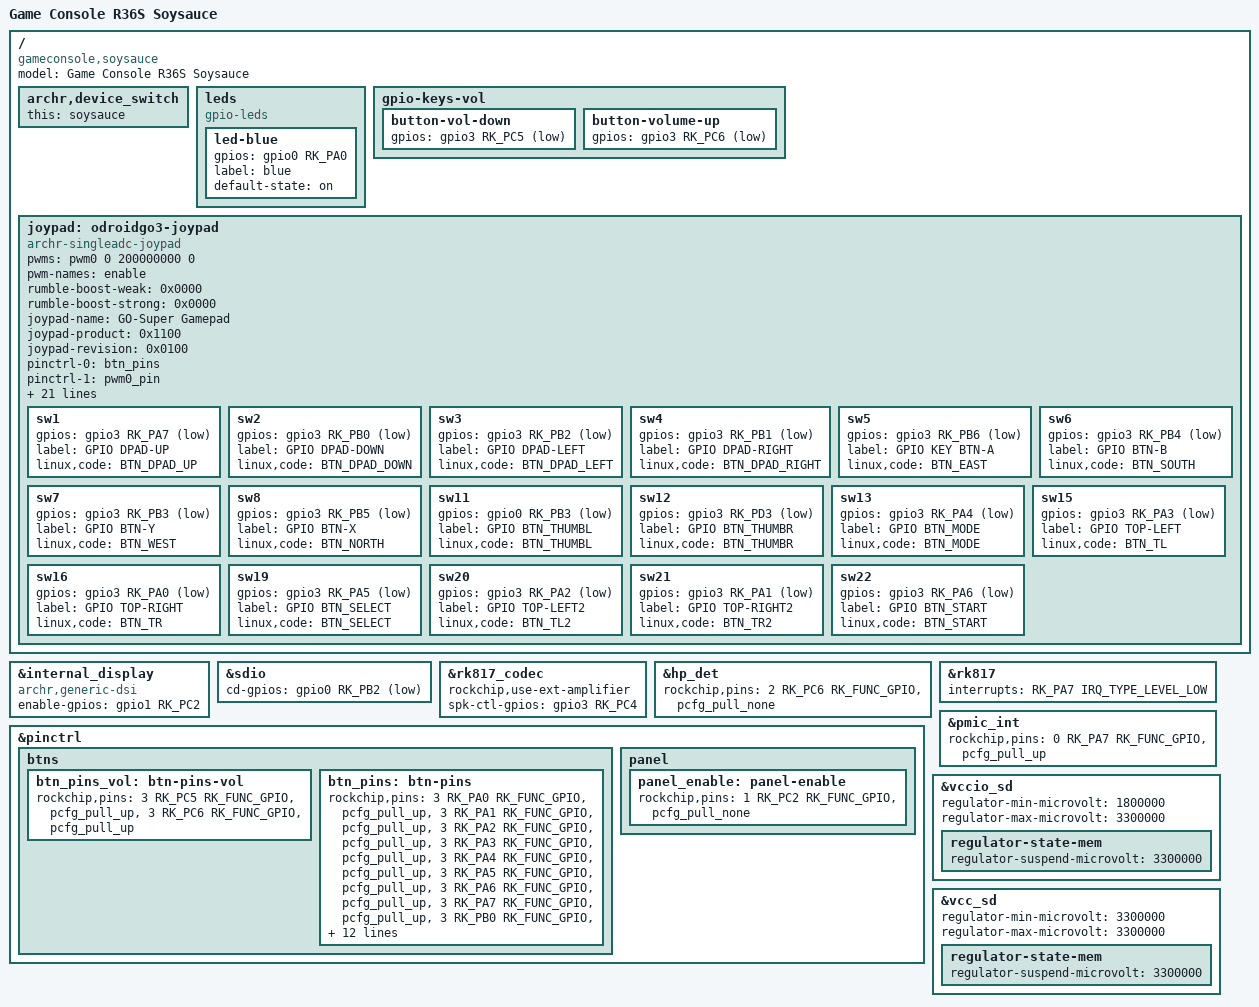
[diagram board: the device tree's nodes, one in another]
// SPDX-License-Identifier: (GPL-2.0+ OR MIT)
/*
 * Copyright (C) 2026 ArchR (https://github.com/archr-linux/Arch-R)
 *
 * Device tree for R36S "soysauce" variant (Y3506 boards).
 * Hardware differences from standard R36S:
 *   - All buttons on GPIO3 (standard uses GPIO1/GPIO2)
 *   - Analog mux on GPIO0 (standard uses GPIO3)
 *   - Panel reset GPIO: GPIO3_PB0
 *   - Panel enable GPIO: GPIO1_PC2
 *   - amux-channel-mapping reordered
 *   - Different joypad product ID (0x1100 "GO-Super Gamepad")
 */

/dts-v1/;
#include "rk3326-gameconsole-r3xs.dtsi"
#include "rk3326-device-group-r36.dtsi"

/ {
	model = "Game Console R36S Soysauce";
	compatible = "gameconsole,soysauce", "gameconsole,r36s", "rockchip,rk3326";

	archr,device_switch {
		this = "soysauce";
	};

	/* LED indicators (soysauce-specific). Only the blue power LED is
	 * GPIO-driven; the red one is hardwired to the charger IC (toggling
	 * the old led-red node on GPIO0_A5 did nothing on hardware, so the
	 * node was a phantom and got dropped). The line is active HIGH:
	 * declaring it active low inverted the whole ES power LED menu
	 * (off lit the LED, on darkened it, heartbeat looked normal). */
	leds {
		compatible = "gpio-leds";

		led-blue {
			gpios = <&gpio0 RK_PA0 GPIO_ACTIVE_HIGH>;
			label = "blue";
			default-state = "on";
		};
	};

	/* Volume buttons: GPIO3_PC6/PC5 on soysauce (base has GPIO2_PA0/PA1) */
	gpio-keys-vol {
		button-vol-down {
			gpios = <&gpio3 RK_PC5 GPIO_ACTIVE_LOW>;
		};

		button-volume-up {
			gpios = <&gpio3 RK_PC6 GPIO_ACTIVE_LOW>;
		};
	};

	joypad: odroidgo3-joypad {
		/* All Y3506 (soysauce) boards we've seen use single-ADC + amux
		 * (amux-count=4, amux-channel-mapping=<3 2 0 1>), which is the
		 * archr-singleadc-joypad driver's wire protocol. The previous
		 * "archr-joypad" / "odroidgo3-joypad" compat strings bind to
		 * the multi-ADC driver, which ignores the amux-* props and
		 * leaves the analog sticks dead (see archr-linux/Arch-R#27).
		 */
		compatible = "archr-singleadc-joypad";
		pwms = <&pwm0 0 200000000 0>;
		pwm-names = "enable";
		rumble-boost-weak = <0x0000>;
		rumble-boost-strong = <0x0000>;

		joypad-name = "GO-Super Gamepad";
		joypad-product = <0x1100>;
		joypad-revision = <0x0100>;

		status = "okay";

		pinctrl-names = "default";
		pinctrl-0 = <&btn_pins>;
		pinctrl-1 = <&pwm0_pin>;

		/* Analog mux on GPIO0 (different from standard R36S) */
		io-channel-names = "amux_adc";
		io-channels = <&saradc 1>;

		amux-count = <4>;
		amux-channel-mapping = <3 2 0 1>;
		amux-a-gpios = <&gpio0 RK_PB5 GPIO_ACTIVE_LOW>;
		amux-b-gpios = <&gpio0 RK_PB4 GPIO_ACTIVE_LOW>;
		amux-en-gpios = <&gpio0 RK_PC1 GPIO_ACTIVE_LOW>;

		button-adc-scale = <2>;
		button-adc-deadzone = <64>;
		button-adc-fuzz = <32>;
		button-adc-flat = <32>;

		/*
		 * The Y3506 analog sticks only swing to ~76% of the declared
		 * range at full deflection with the default 200 gain (measured
		 * ~1365 of 1800 via evtest), so partial pushes never cross the
		 * EmulationStation navigation threshold and menu scrolling needs
		 * several flicks per item. Bump the gain so full deflection
		 * saturates the axis; games keep all but the top few percent of
		 * travel. The R36S/eeclone pots reach full range at 200, this is
		 * a Y3506-specific calibration.
		 */
		abs_x-p-tuning = <280>;
		abs_x-n-tuning = <280>;
		abs_y-p-tuning = <280>;
		abs_y-n-tuning = <280>;
		abs_rx-p-tuning = <280>;
		abs_rx-n-tuning = <280>;
		abs_ry-p-tuning = <280>;
		abs_ry-n-tuning = <280>;

		poll-interval = <10>;

		invert-absx;
		invert-absy;

		/* All buttons on GPIO3 (soysauce layout) */
		sw1 {
			gpios = <&gpio3 RK_PA7 GPIO_ACTIVE_LOW>;
			label = "GPIO DPAD-UP";
			linux,code = <BTN_DPAD_UP>;
		};
		sw2 {
			gpios = <&gpio3 RK_PB0 GPIO_ACTIVE_LOW>;
			label = "GPIO DPAD-DOWN";
			linux,code = <BTN_DPAD_DOWN>;
		};
		sw3 {
			gpios = <&gpio3 RK_PB2 GPIO_ACTIVE_LOW>;
			label = "GPIO DPAD-LEFT";
			linux,code = <BTN_DPAD_LEFT>;
		};
		sw4 {
			gpios = <&gpio3 RK_PB1 GPIO_ACTIVE_LOW>;
			label = "GPIO DPAD-RIGHT";
			linux,code = <BTN_DPAD_RIGHT>;
		};
		sw5 {
			gpios = <&gpio3 RK_PB6 GPIO_ACTIVE_LOW>;
			label = "GPIO KEY BTN-A";
			linux,code = <BTN_EAST>;
		};
		sw6 {
			gpios = <&gpio3 RK_PB4 GPIO_ACTIVE_LOW>;
			label = "GPIO BTN-B";
			linux,code = <BTN_SOUTH>;
		};
		sw7 {
			gpios = <&gpio3 RK_PB3 GPIO_ACTIVE_LOW>;
			label = "GPIO BTN-Y";
			linux,code = <BTN_WEST>;
		};
		sw8 {
			gpios = <&gpio3 RK_PB5 GPIO_ACTIVE_LOW>;
			label = "GPIO BTN-X";
			linux,code = <BTN_NORTH>;
		};
		sw11 {
			gpios = <&gpio0 RK_PB3 GPIO_ACTIVE_LOW>;
			label = "GPIO BTN_THUMBL";
			linux,code = <BTN_THUMBL>;
		};
		sw12 {
			gpios = <&gpio3 RK_PD3 GPIO_ACTIVE_LOW>;
			label = "GPIO BTN_THUMBR";
			linux,code = <BTN_THUMBR>;
		};
		sw13 {
			gpios = <&gpio3 RK_PA4 GPIO_ACTIVE_LOW>;
			label = "GPIO BTN_MODE";
			linux,code = <BTN_MODE>;
		};
		sw15 {
			gpios = <&gpio3 RK_PA3 GPIO_ACTIVE_LOW>;
			label = "GPIO TOP-LEFT";
			linux,code = <BTN_TL>;
		};
		sw16 {
			gpios = <&gpio3 RK_PA0 GPIO_ACTIVE_LOW>;
			label = "GPIO TOP-RIGHT";
			linux,code = <BTN_TR>;
		};
		sw19 {
			gpios = <&gpio3 RK_PA5 GPIO_ACTIVE_LOW>;
			label = "GPIO BTN_SELECT";
			linux,code = <BTN_SELECT>;
		};
		sw20 {
			gpios = <&gpio3 RK_PA2 GPIO_ACTIVE_LOW>;
			label = "GPIO TOP-LEFT2";
			linux,code = <BTN_TL2>;
		};
		sw21 {
			gpios = <&gpio3 RK_PA1 GPIO_ACTIVE_LOW>;
			label = "GPIO TOP-RIGHT2";
			linux,code = <BTN_TR2>;
		};
		sw22 {
			gpios = <&gpio3 RK_PA6 GPIO_ACTIVE_LOW>;
			label = "GPIO BTN_START";
			linux,code = <BTN_START>;
		};
	};
};

/* Soysauce panel: same reset GPIO as base (GPIO3_PC0), add enable GPIO */
&internal_display {
	compatible = "archr,generic-dsi", "rocknix,generic-dsi";
	enable-gpios = <&gpio1 RK_PC2 GPIO_ACTIVE_HIGH>;
};

/*
 * Slot 2 (TF2) card detect. The base puts it on GPIO3_PB6, which is BTN-A
 * here; every Y3506 vendor DTB (V03 to V05) wires it to GPIO0_PB2, free on
 * this board since the PMIC interrupt moved to GPIO0_PA7 (see &rk817). With
 * the real line the slot is hot-pluggable and a card that fails its first
 * init gets probed again on reinsertion, instead of the one boot-time try a
 * non-removable slot gets. The RK915 wifi overlay sets non-removable on
 * &sdio itself, which leaves this line inert on those boards.
 */
&sdio {
	cd-gpios = <&gpio0 RK_PB2 GPIO_ACTIVE_LOW>;
};

&rk817_codec {
	/*
	 * The loudspeaker is not on the rk817 class-D SPKO output; it hangs off
	 * the analog headphone output through an external amp enabled by
	 * spk-ctl-gpios. Tell the codec driver to route the speaker path through
	 * the headphone DACs and toggle that GPIO (see the rk817 ext-amplifier
	 * patch) instead of driving the unused class-D.
	 */
	rockchip,use-ext-amplifier;
	spk-ctl-gpios = <&gpio3 RK_PC4 GPIO_ACTIVE_HIGH>;
};

/*
 * The shared r3xs hp-det pin uses pcfg_pull_down, which on this board pins the
 * headphone-detect line low forever (insertion is never seen). The stock R35S
 * DTB leaves it at pcfg_pull_none and lets the jack circuit drive the level, so
 * override the pull here for the Soysauce only.
 */
&hp_det {
	rockchip,pins = <2 RK_PC6 RK_FUNC_GPIO &pcfg_pull_none>;
};

&pinctrl {
	btns {
		btn_pins_vol: btn-pins-vol {
			rockchip,pins = <3 RK_PC5 RK_FUNC_GPIO &pcfg_pull_up>,
					<3 RK_PC6 RK_FUNC_GPIO &pcfg_pull_up>;
		};

		btn_pins: btn-pins {
			rockchip,pins =
				<3 RK_PA0 RK_FUNC_GPIO &pcfg_pull_up>,
				<3 RK_PA1 RK_FUNC_GPIO &pcfg_pull_up>,
				<3 RK_PA2 RK_FUNC_GPIO &pcfg_pull_up>,
				<3 RK_PA3 RK_FUNC_GPIO &pcfg_pull_up>,
				<3 RK_PA4 RK_FUNC_GPIO &pcfg_pull_up>,
				<3 RK_PA5 RK_FUNC_GPIO &pcfg_pull_up>,
				<3 RK_PA6 RK_FUNC_GPIO &pcfg_pull_up>,
				<3 RK_PA7 RK_FUNC_GPIO &pcfg_pull_up>,
				<3 RK_PB0 RK_FUNC_GPIO &pcfg_pull_up>,
				<3 RK_PB1 RK_FUNC_GPIO &pcfg_pull_up>,
				<3 RK_PB2 RK_FUNC_GPIO &pcfg_pull_up>,
				<3 RK_PB3 RK_FUNC_GPIO &pcfg_pull_up>,
				<3 RK_PB4 RK_FUNC_GPIO &pcfg_pull_up>,
				<3 RK_PB5 RK_FUNC_GPIO &pcfg_pull_up>,
				<3 RK_PB6 RK_FUNC_GPIO &pcfg_pull_up>,
				<3 RK_PD3 RK_FUNC_GPIO &pcfg_pull_up>,
				<0 RK_PB3 RK_FUNC_GPIO &pcfg_pull_up>,
				<0 RK_PB4 RK_FUNC_GPIO &pcfg_pull_up>,
				<0 RK_PB5 RK_FUNC_GPIO &pcfg_pull_up>,
				<0 RK_PC1 RK_FUNC_GPIO &pcfg_pull_up>;
		};
	};

	panel {
		panel_enable: panel-enable {
			rockchip,pins = <1 RK_PC2 RK_FUNC_GPIO &pcfg_pull_none>;
		};
	};
};

/* The Soysauce routes the PMIC interrupt to GPIO0_A7, not the GPIO0_B2
 * the rest of the family uses (vendor DTB pmic_int pinctrl says pin 7).
 * With the wrong pin every rk817 interrupt is lost: power key, jack
 * detect, charger plug events and the suspend wake path (verified live:
 * /proc/interrupts stayed at zero across button presses). */
&rk817 {
	interrupts = <RK_PA7 IRQ_TYPE_LEVEL_LOW>;
};

&pmic_int {
	rockchip,pins = <0 RK_PA7 RK_FUNC_GPIO &pcfg_pull_up>;
};

/*
 * SD card power as the Y3506 boards ship it (every vendor DTB, V03 to
 * V06): the card at 3.3 V and its I/O switching between 3.3 V and 1.8 V.
 * The R36S values inherited from r3xs.dtsi (card up to 3.0 V, I/O fixed at
 * 1.8 V) suit the R36S, whose stock DTB has them, not this board: a card
 * starts at 3.3 V signaling and must get back to it to recover, and
 * Soysauce users saw the console freeze at random until reset, even while
 * booting, the way every task waits on a card that stopped answering.
 */
&vccio_sd {
	regulator-min-microvolt = <1800000>;
	regulator-max-microvolt = <3300000>;

	regulator-state-mem {
		regulator-suspend-microvolt = <3300000>;
	};
};

&vcc_sd {
	regulator-min-microvolt = <3300000>;
	regulator-max-microvolt = <3300000>;

	regulator-state-mem {
		regulator-suspend-microvolt = <3300000>;
	};
};
